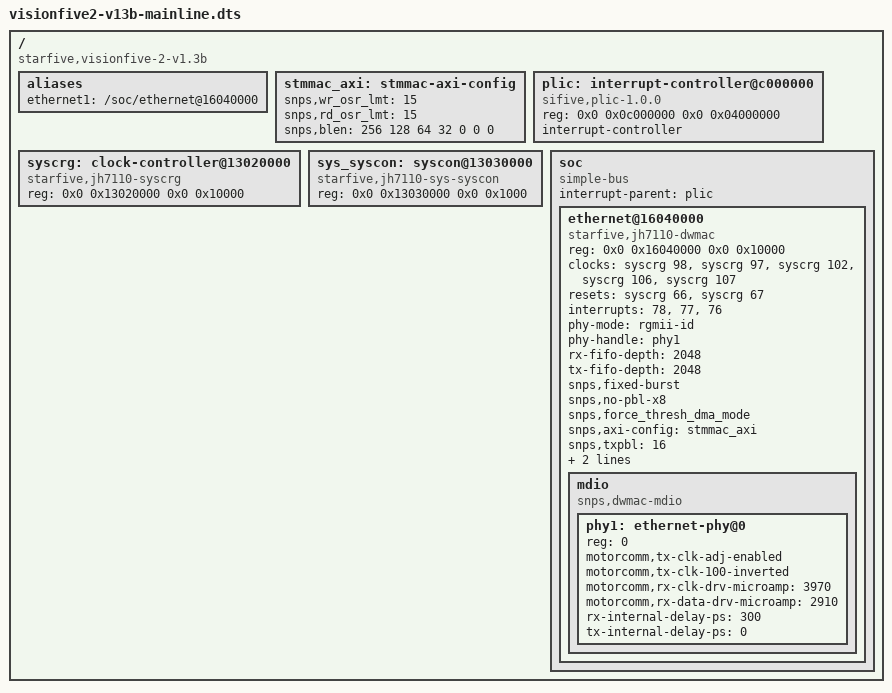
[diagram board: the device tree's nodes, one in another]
/dts-v1/;

/ {
    compatible = "starfive,visionfive-2-v1.3b", "starfive,jh7110";
    #address-cells = <2>;
    #size-cells = <2>;

    aliases {
        ethernet1 = "/soc/ethernet@16040000";
    };

    stmmac_axi: stmmac-axi-config {
        snps,wr_osr_lmt = <15>;
        snps,rd_osr_lmt = <15>;
        snps,blen = <256 128 64 32 0 0 0>;
    };

    plic: interrupt-controller@c000000 {
        compatible = "sifive,plic-1.0.0";
        reg = <0x0 0x0c000000 0x0 0x04000000>;
        interrupt-controller;
        #interrupt-cells = <1>;
    };

    syscrg: clock-controller@13020000 {
        compatible = "starfive,jh7110-syscrg";
        reg = <0x0 0x13020000 0x0 0x10000>;
        #clock-cells = <1>;
        #reset-cells = <1>;
    };

    sys_syscon: syscon@13030000 {
        compatible = "starfive,jh7110-sys-syscon", "syscon";
        reg = <0x0 0x13030000 0x0 0x1000>;
    };

    soc {
        compatible = "simple-bus";
        #address-cells = <2>;
        #size-cells = <2>;
        ranges;
        interrupt-parent = <&plic>;

        ethernet@16040000 {
            compatible = "starfive,jh7110-dwmac", "snps,dwmac-5.20";
            reg = <0x0 0x16040000 0x0 0x10000>;
            clocks = <&syscrg 98>, <&syscrg 97>, <&syscrg 102>,
                     <&syscrg 106>, <&syscrg 107>;
            clock-names = "stmmaceth", "pclk", "ptp_ref", "tx", "gtx";
            resets = <&syscrg 66>, <&syscrg 67>;
            reset-names = "stmmaceth", "ahb";
            interrupts = <78>, <77>, <76>;
            interrupt-names = "macirq", "eth_wake_irq", "eth_lpi";
            phy-mode = "rgmii-id";
            phy-handle = <&phy1>;
            rx-fifo-depth = <2048>;
            tx-fifo-depth = <2048>;
            snps,fixed-burst;
            snps,no-pbl-x8;
            snps,force_thresh_dma_mode;
            snps,axi-config = <&stmmac_axi>;
            snps,txpbl = <16>;
            snps,rxpbl = <16>;
            starfive,syscon = <&sys_syscon 0x90 0x2>;
            status = "okay";

            mdio {
                compatible = "snps,dwmac-mdio";
                #address-cells = <1>;
                #size-cells = <0>;

                phy1: ethernet-phy@0 {
                    reg = <0>;
                    motorcomm,tx-clk-adj-enabled;
                    motorcomm,tx-clk-100-inverted;
                    motorcomm,rx-clk-drv-microamp = <3970>;
                    motorcomm,rx-data-drv-microamp = <2910>;
                    rx-internal-delay-ps = <300>;
                    tx-internal-delay-ps = <0>;
                };
            };
        };
    };
};
